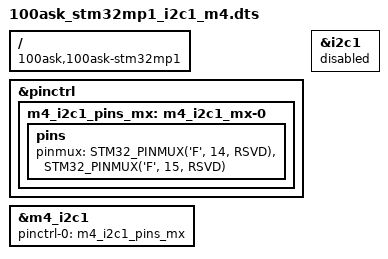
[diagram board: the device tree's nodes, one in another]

/*
 * Device tree overlay for i2c1
 */

#include "dt-bindings/gpio/gpio.h"
#include "dt-bindings/pinctrl/stm32-pinfunc.h"

/dts-v1/;
/plugin/;

/ {
     compatible = "100ask,100ask-stm32mp1", "st,stm32mp157";
    fragment@0 {
        target = <&pinctrl>;
        __overlay__ {
			m4_i2c1_pins_mx: m4_i2c1_mx-0 {
				pins {
					pinmux = <STM32_PINMUX('F', 14, RSVD)>, /* I2C1_SCL */
							 <STM32_PINMUX('F', 15, RSVD)>; /* I2C1_SDA */
				};
			};
		};
    };
	
    fragment@1 {
        target = <&i2c1>;
        __overlay__ {
			status = "disable";
        };
    };
	
	fragment@2 {
        target = <&m4_i2c1>;
        __overlay__ {
			pinctrl-names = "default";
			pinctrl-0 = <&m4_i2c1_pins_mx>;
			status = "okay";
        };
    };
};

